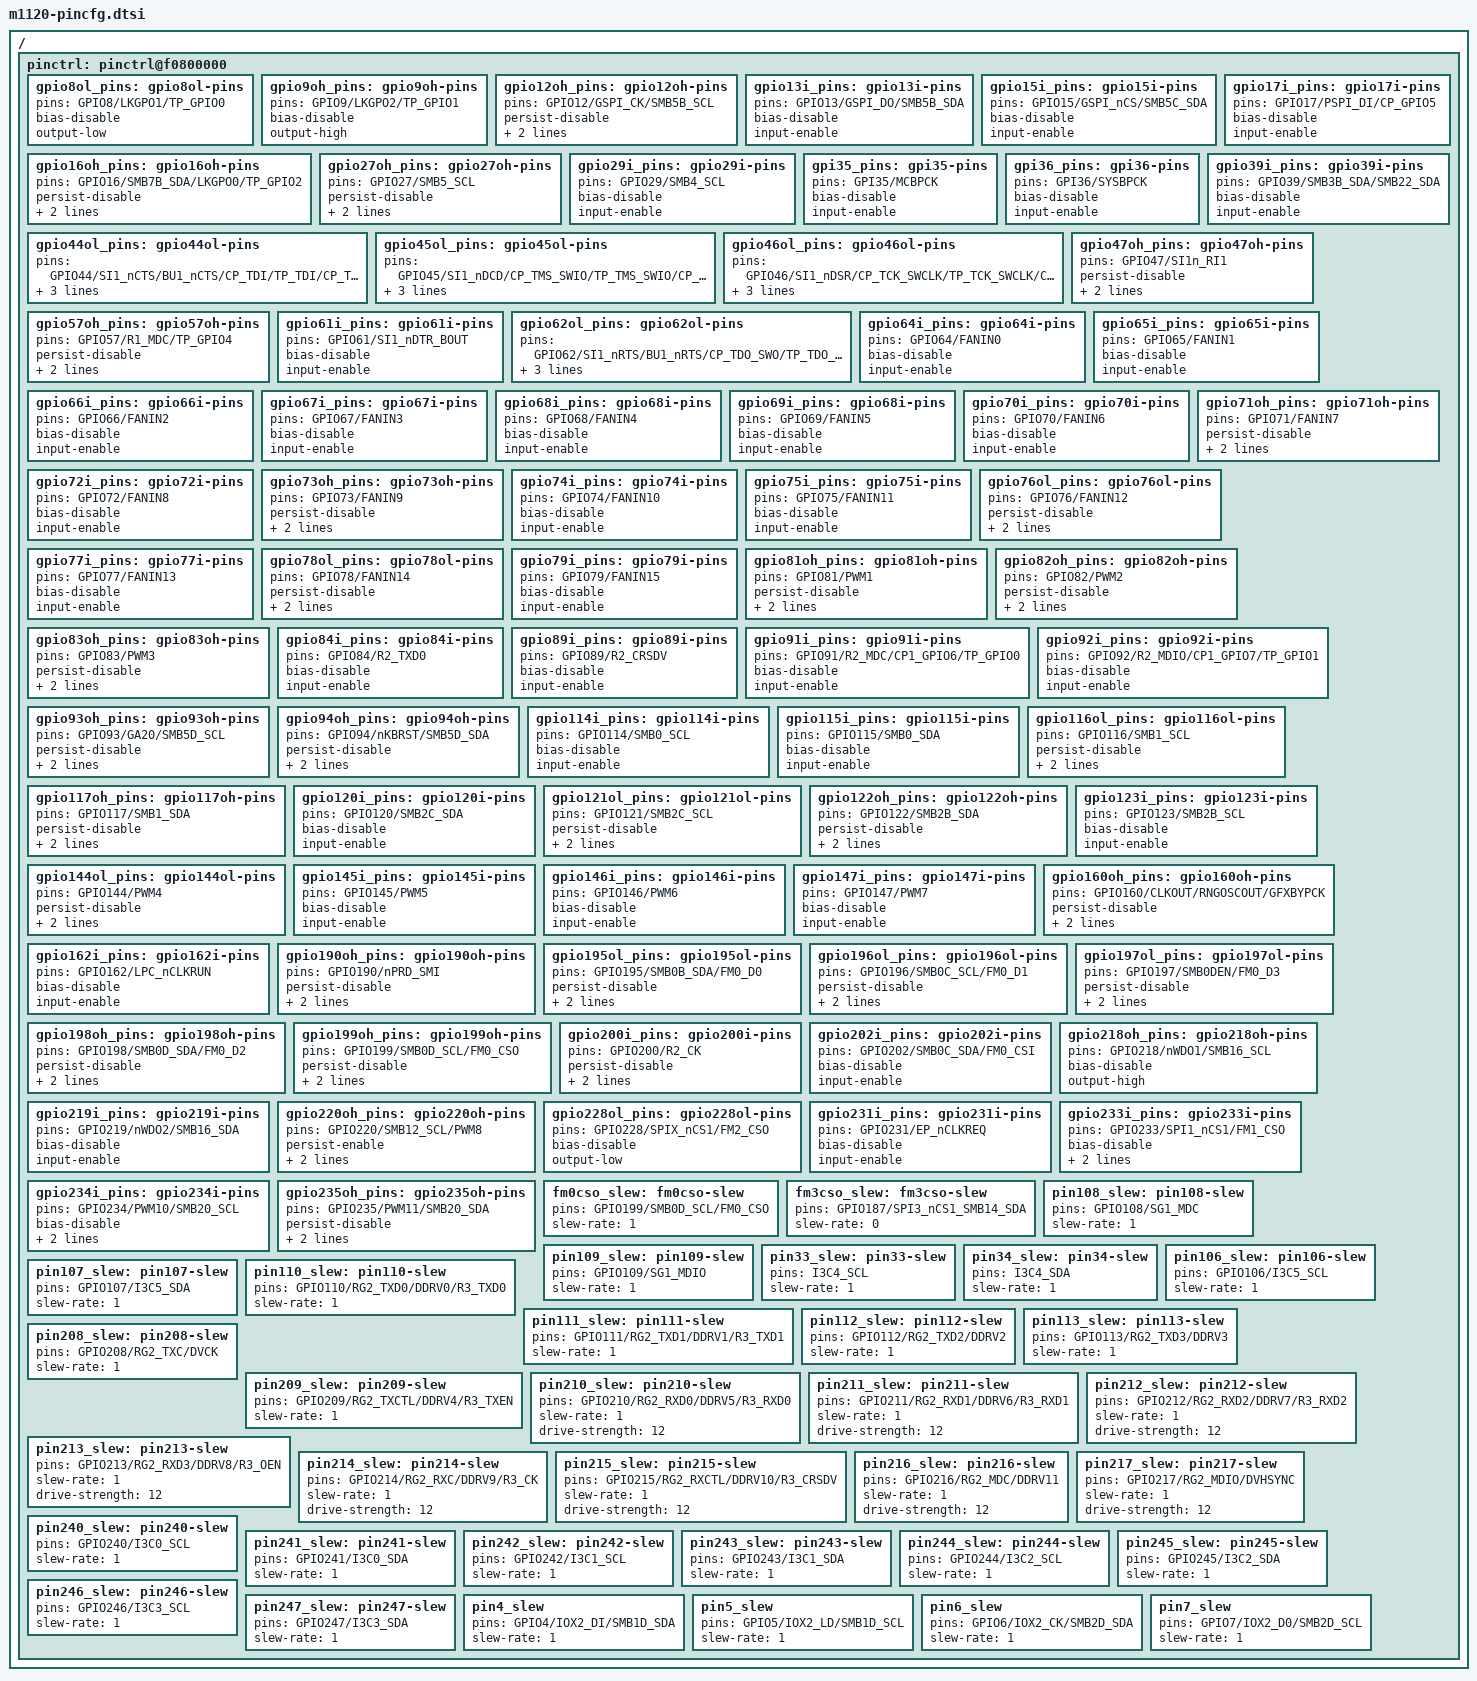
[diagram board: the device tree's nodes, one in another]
// SPDX-License-Identifier: GPL-2.0
// Copyright (c) 2018 Nuvoton Technology

/ {
	pinctrl: pinctrl@f0800000 {
		gpio8ol_pins: gpio8ol-pins {
			pins = "GPIO8/LKGPO1/TP_GPIO0";
			bias-disable;
			output-low;
		};
		gpio9oh_pins: gpio9oh-pins {
			pins = "GPIO9/LKGPO2/TP_GPIO1";
			bias-disable;
			output-high;
		};
		gpio12oh_pins: gpio12oh-pins {
			pins = "GPIO12/GSPI_CK/SMB5B_SCL";
			persist-disable;
			bias-disable;
			output-high;
		};
		gpio13i_pins: gpio13i-pins {
			pins = "GPIO13/GSPI_DO/SMB5B_SDA";
			bias-disable;
			input-enable;
		};
		gpio15i_pins: gpio15i-pins {
			pins = "GPIO15/GSPI_nCS/SMB5C_SDA";
			bias-disable;
			input-enable;
		};
		gpio16oh_pins: gpio16oh-pins {
			pins = "GPIO16/SMB7B_SDA/LKGPO0/TP_GPIO2";
			persist-disable;
			bias-disable;
			output-high;
		};
		gpio17i_pins: gpio17i-pins {
			pins = "GPIO17/PSPI_DI/CP_GPIO5";
			bias-disable;
			input-enable;
		};
		gpio27oh_pins: gpio27oh-pins {
			pins = "GPIO27/SMB5_SCL";
			persist-disable;
			bias-disable;
			output-high;
		};
		gpio29i_pins: gpio29i-pins {
			pins = "GPIO29/SMB4_SCL";
			bias-disable;
			input-enable;
		};
		gpi35_pins: gpi35-pins {
			pins = "GPI35/MCBPCK";
			bias-disable;
			input-enable;
		};
		gpi36_pins: gpi36-pins {
			pins = "GPI36/SYSBPCK";
			bias-disable;
			input-enable;
		};
		gpio39i_pins: gpio39i-pins {
			pins = "GPIO39/SMB3B_SDA/SMB22_SDA";
			bias-disable;
			input-enable;
		};
		gpio44ol_pins: gpio44ol-pins {
			pins = "GPIO44/SI1_nCTS/BU1_nCTS/CP_TDI/TP_TDI/CP_TP_TDI";
			persist-disable;
			bias-disable;
			output-low;
		};
		gpio45ol_pins: gpio45ol-pins {
			pins = "GPIO45/SI1_nDCD/CP_TMS_SWIO/TP_TMS_SWIO/CP_TP_TMS_SWIO";
			persist-disable;
			bias-disable;
			output-low;
		};
		gpio46ol_pins: gpio46ol-pins {
			pins = "GPIO46/SI1_nDSR/CP_TCK_SWCLK/TP_TCK_SWCLK/CP_TP_TCK_SWCLK";
			persist-disable;
			bias-disable;
			output-low;
		};
		gpio47oh_pins: gpio47oh-pins {
			pins = "GPIO47/SI1n_RI1";
			persist-disable;
			bias-disable;
			output-high;
		};

		gpio57oh_pins: gpio57oh-pins {
			pins = "GPIO57/R1_MDC/TP_GPIO4";
			persist-disable;
			bias-disable;
			output-high;
		};
		gpio61i_pins: gpio61i-pins {
			pins = "GPIO61/SI1_nDTR_BOUT";
			bias-disable;
			input-enable;
		};
		gpio62ol_pins: gpio62ol-pins {
			pins = "GPIO62/SI1_nRTS/BU1_nRTS/CP_TDO_SWO/TP_TDO_SWO/CP_TP_TDO_SWO";
			persist-disable;
			bias-disable;
			output-low;
		};
		gpio64i_pins: gpio64i-pins {
			pins = "GPIO64/FANIN0";
			bias-disable;
			input-enable;
		};
		gpio65i_pins: gpio65i-pins {
			pins = "GPIO65/FANIN1";
			bias-disable;
			input-enable;
		};
		gpio66i_pins: gpio66i-pins {
			pins = "GPIO66/FANIN2";
			bias-disable;
			input-enable;
		};
		gpio67i_pins: gpio67i-pins {
			pins = "GPIO67/FANIN3";
			bias-disable;
			input-enable;
		};
		gpio68i_pins: gpio68i-pins {
			pins = "GPIO68/FANIN4";
			bias-disable;
			input-enable;
		};
		gpio69i_pins: gpio68i-pins {
			pins = "GPIO69/FANIN5";
			bias-disable;
			input-enable;
		};
		gpio70i_pins: gpio70i-pins {
			pins = "GPIO70/FANIN6";
			bias-disable;
			input-enable;
		};
		gpio71oh_pins: gpio71oh-pins {
			pins = "GPIO71/FANIN7";
			persist-disable;
			bias-disable;
			output-high;
		};
		gpio72i_pins: gpio72i-pins {
			pins = "GPIO72/FANIN8";
			bias-disable;
			input-enable;
		};
		gpio73oh_pins: gpio73oh-pins {
			pins = "GPIO73/FANIN9";
			persist-disable;
			bias-disable;
			output-high;
		};
		gpio74i_pins: gpio74i-pins {
			pins = "GPIO74/FANIN10";
			bias-disable;
			input-enable;
		};
		gpio75i_pins: gpio75i-pins {
			pins = "GPIO75/FANIN11";
			bias-disable;
			input-enable;
		};
		gpio76ol_pins: gpio76ol-pins {
			pins = "GPIO76/FANIN12";
			persist-disable;
			bias-disable;
			output-low;
		};
		gpio77i_pins: gpio77i-pins {
			pins = "GPIO77/FANIN13";
			bias-disable;
			input-enable;
		};
		gpio78ol_pins: gpio78ol-pins {
			pins = "GPIO78/FANIN14";
			persist-disable;
			bias-disable;
			output-low;
		};
		gpio79i_pins: gpio79i-pins {
			pins = "GPIO79/FANIN15";
			bias-disable;
			input-enable;
		};
		gpio81oh_pins: gpio81oh-pins {
			pins = "GPIO81/PWM1";
			persist-disable;
			bias-disable;
			output-high;
		};
		gpio82oh_pins: gpio82oh-pins {
			pins = "GPIO82/PWM2";
			persist-disable;
			bias-disable;
			output-high;
		};
		gpio83oh_pins: gpio83oh-pins {
			pins = "GPIO83/PWM3";
			persist-disable;
			bias-disable;
			output-high;
		};
		gpio84i_pins: gpio84i-pins {
			pins = "GPIO84/R2_TXD0";
			bias-disable;
			input-enable;
		};
		gpio89i_pins: gpio89i-pins {
			pins = "GPIO89/R2_CRSDV";
			bias-disable;
			input-enable;
		};
		gpio91i_pins: gpio91i-pins {
			pins = "GPIO91/R2_MDC/CP1_GPIO6/TP_GPIO0";
			bias-disable;
			input-enable;
		};
		gpio92i_pins: gpio92i-pins {
			pins = "GPIO92/R2_MDIO/CP1_GPIO7/TP_GPIO1";
			bias-disable;
			input-enable;
		};
		gpio93oh_pins: gpio93oh-pins {
			pins = "GPIO93/GA20/SMB5D_SCL";
			persist-disable;
			bias-disable;
			output-high;
		};
		gpio94oh_pins: gpio94oh-pins {
			pins = "GPIO94/nKBRST/SMB5D_SDA";
			persist-disable;
			bias-disable;
			output-high;
		};
		gpio114i_pins: gpio114i-pins {
			pins = "GPIO114/SMB0_SCL";
			bias-disable;
			input-enable;
		};
		gpio115i_pins: gpio115i-pins {
			pins = "GPIO115/SMB0_SDA";
			bias-disable;
			input-enable;
		};
		gpio116ol_pins: gpio116ol-pins {
			pins = "GPIO116/SMB1_SCL";
			persist-disable;
			bias-disable;
			output-low;
		};
		gpio117oh_pins: gpio117oh-pins {
			pins = "GPIO117/SMB1_SDA";
			persist-disable;
			bias-disable;
			output-high;
		};
		gpio120i_pins: gpio120i-pins {
			pins = "GPIO120/SMB2C_SDA";
			bias-disable;
			input-enable;

		};
		gpio121ol_pins: gpio121ol-pins {
			pins = "GPIO121/SMB2C_SCL";
			persist-disable;
			bias-disable;
			output-low;
		};
		gpio122oh_pins: gpio122oh-pins {
			pins = "GPIO122/SMB2B_SDA";
			persist-disable;
			bias-disable;
			output-high;
		};
		gpio123i_pins: gpio123i-pins {
			pins = "GPIO123/SMB2B_SCL";
			bias-disable;
			input-enable;
		};
		gpio144ol_pins: gpio144ol-pins {
			pins = "GPIO144/PWM4";
			persist-disable;
			bias-disable;
			output-low;
		};
		gpio145i_pins: gpio145i-pins {
			pins = "GPIO145/PWM5";
			bias-disable;
			input-enable;
		};
		gpio146i_pins: gpio146i-pins {
			pins = "GPIO146/PWM6";
			bias-disable;
			input-enable;
		};
		gpio147i_pins: gpio147i-pins {
			pins = "GPIO147/PWM7";
			bias-disable;
			input-enable;
		};
		gpio160oh_pins: gpio160oh-pins {
			pins = "GPIO160/CLKOUT/RNGOSCOUT/GFXBYPCK";
			persist-disable;
			bias-disable;
			output-high;
		};
		gpio162i_pins: gpio162i-pins {
			pins = "GPIO162/LPC_nCLKRUN";
			bias-disable;
			input-enable;
		};
		gpio190oh_pins: gpio190oh-pins {
			pins = "GPIO190/nPRD_SMI";
			persist-disable;
			bias-disable;
			output-high;
		};
		gpio195ol_pins: gpio195ol-pins {
			pins = "GPIO195/SMB0B_SDA/FM0_D0";
			persist-disable;
			bias-disable;
			output-low;
		};
		gpio196ol_pins: gpio196ol-pins {
			pins = "GPIO196/SMB0C_SCL/FM0_D1";
			persist-disable;
			bias-disable;
			output-low;
		};
		gpio197ol_pins: gpio197ol-pins {
			pins = "GPIO197/SMB0DEN/FM0_D3";
			persist-disable;
			bias-disable;
			output-low;
		};
		gpio198oh_pins: gpio198oh-pins {
			pins = "GPIO198/SMB0D_SDA/FM0_D2";
			persist-disable;
			bias-disable;
			output-high;
		};
		gpio199oh_pins: gpio199oh-pins {
			pins = "GPIO199/SMB0D_SCL/FM0_CSO";
			persist-disable;
			bias-disable;
			output-high;
		};
		gpio200i_pins: gpio200i-pins {
			pins = "GPIO200/R2_CK";
			persist-disable;
			bias-disable;
			input-enable;
		};
		gpio202i_pins: gpio202i-pins {
			pins = "GPIO202/SMB0C_SDA/FM0_CSI";
			bias-disable;
			input-enable;
		};
		gpio218oh_pins: gpio218oh-pins {
			pins = "GPIO218/nWDO1/SMB16_SCL";
			bias-disable;
			output-high;
		};
		gpio219i_pins: gpio219i-pins {
			pins = "GPIO219/nWDO2/SMB16_SDA";
			bias-disable;
			input-enable;
		};
		gpio220oh_pins: gpio220oh-pins {
			pins = "GPIO220/SMB12_SCL/PWM8";
			persist-enable;
			bias-disable;
			output-high;
		};
		gpio228ol_pins: gpio228ol-pins {
			pins = "GPIO228/SPIX_nCS1/FM2_CSO";
			bias-disable;
			output-low;
		};
		gpio231i_pins: gpio231i-pins {
			pins = "GPIO231/EP_nCLKREQ";
			bias-disable;
			input-enable;
		};
		gpio233i_pins: gpio233i-pins {
			pins = "GPIO233/SPI1_nCS1/FM1_CSO";
			bias-disable;
			input-enable;
			event-clear;
		};
		gpio234i_pins: gpio234i-pins {
			pins = "GPIO234/PWM10/SMB20_SCL";
			bias-disable;
			input-enable;
			event-clear;
		};
		gpio235oh_pins: gpio235oh-pins {
			pins = "GPIO235/PWM11/SMB20_SDA";
			persist-disable;
			bias-disable;
			output-high;
		};

		fm0cso_slew: fm0cso-slew {
			pins = "GPIO199/SMB0D_SCL/FM0_CSO";
			slew-rate = <1>;
		};
		fm3cso_slew: fm3cso-slew {
			pins = "GPIO187/SPI3_nCS1_SMB14_SDA";
			slew-rate = <0>;
		};
		pin108_slew: pin108-slew {
			pins = "GPIO108/SG1_MDC";
			slew-rate = <1>;
		};
		pin109_slew: pin109-slew {
			pins = "GPIO109/SG1_MDIO";
			slew-rate = <1>;
		};
		pin33_slew: pin33-slew {
			pins = "I3C4_SCL";
			slew-rate = <1>;
		};
		pin34_slew: pin34-slew {
			pins = "I3C4_SDA";
			slew-rate = <1>;
		};
		pin106_slew: pin106-slew {
			pins = "GPIO106/I3C5_SCL";
			slew-rate = <1>;
		};
		pin107_slew: pin107-slew {
			pins = "GPIO107/I3C5_SDA";
			slew-rate = <1>;
		};
		pin110_slew: pin110-slew {
			pins = "GPIO110/RG2_TXD0/DDRV0/R3_TXD0";
			slew-rate = <1>;
		};
		pin111_slew: pin111-slew {
			pins = "GPIO111/RG2_TXD1/DDRV1/R3_TXD1";
			slew-rate = <1>;
		};
		pin112_slew: pin112-slew {
			pins = "GPIO112/RG2_TXD2/DDRV2";
			slew-rate = <1>;
		};
		pin113_slew: pin113-slew {
			pins = "GPIO113/RG2_TXD3/DDRV3";
			slew-rate = <1>;
		};
		pin208_slew: pin208-slew {
			pins = "GPIO208/RG2_TXC/DVCK";
			slew-rate = <1>;
		};
		pin209_slew: pin209-slew {
			pins = "GPIO209/RG2_TXCTL/DDRV4/R3_TXEN";
			slew-rate = <1>;
		};
		pin210_slew: pin210-slew {
			pins = "GPIO210/RG2_RXD0/DDRV5/R3_RXD0";
			slew-rate = <1>;
			drive-strength = <12>;
		};
		pin211_slew: pin211-slew {
			pins = "GPIO211/RG2_RXD1/DDRV6/R3_RXD1";
			slew-rate = <1>;
			drive-strength = <12>;
		};
		pin212_slew: pin212-slew {
			pins = "GPIO212/RG2_RXD2/DDRV7/R3_RXD2";
			slew-rate = <1>;
			drive-strength = <12>;
		};
		pin213_slew: pin213-slew {
			pins = "GPIO213/RG2_RXD3/DDRV8/R3_OEN";
			slew-rate = <1>;
			drive-strength = <12>;
		};
		pin214_slew: pin214-slew {
			pins = "GPIO214/RG2_RXC/DDRV9/R3_CK";
			slew-rate = <1>;
			drive-strength = <12>;
		};
		pin215_slew: pin215-slew {
			pins = "GPIO215/RG2_RXCTL/DDRV10/R3_CRSDV";
			slew-rate = <1>;
			drive-strength = <12>;
		};
		pin216_slew: pin216-slew {
			pins = "GPIO216/RG2_MDC/DDRV11";
			slew-rate = <1>;
			drive-strength = <12>;
		};
		pin217_slew: pin217-slew {
			pins = "GPIO217/RG2_MDIO/DVHSYNC";
			slew-rate = <1>;
			drive-strength = <12>;
		};
		pin240_slew: pin240-slew {
			pins = "GPIO240/I3C0_SCL";
			slew-rate = <1>;
		};
		pin241_slew: pin241-slew {
			pins = "GPIO241/I3C0_SDA";
			slew-rate = <1>;
		};
		pin242_slew: pin242-slew {
			pins = "GPIO242/I3C1_SCL";
			slew-rate = <1>;
		};
		pin243_slew: pin243-slew {
			pins = "GPIO243/I3C1_SDA";
			slew-rate = <1>;
		};
		pin244_slew: pin244-slew {
			pins = "GPIO244/I3C2_SCL";
			slew-rate = <1>;
		};
		pin245_slew: pin245-slew {
			pins = "GPIO245/I3C2_SDA";
			slew-rate = <1>;
		};
		pin246_slew: pin246-slew {
			pins = "GPIO246/I3C3_SCL";
			slew-rate = <1>;
		};
		pin247_slew: pin247-slew {
			pins = "GPIO247/I3C3_SDA";
			slew-rate = <1>;
		};
		pin4_slew: pin4_slew {
			pins = "GPIO4/IOX2_DI/SMB1D_SDA";
			slew-rate = <1>;
		};
		pin5_slew: pin5_slew {
			pins = "GPIO5/IOX2_LD/SMB1D_SCL";
			slew-rate = <1>;
		};
		pin6_slew: pin6_slew {
			pins = "GPIO6/IOX2_CK/SMB2D_SDA";
			slew-rate = <1>;
		};
		pin7_slew: pin7_slew {
			pins = "GPIO7/IOX2_D0/SMB2D_SCL";
			slew-rate = <1>;
		};
	};
};

